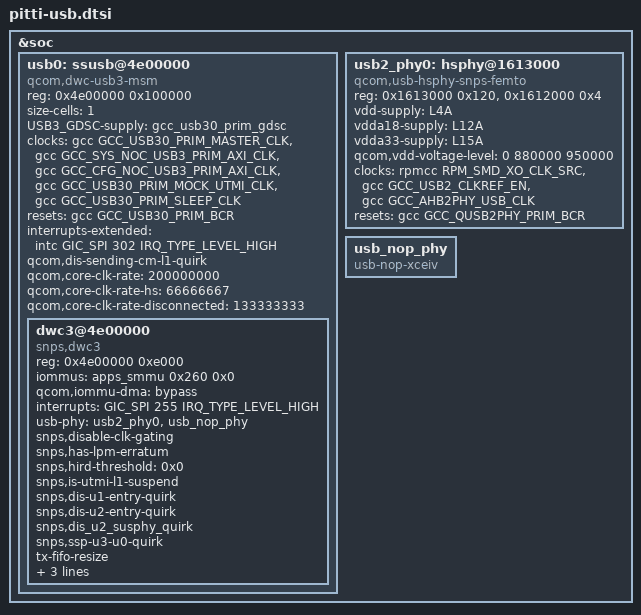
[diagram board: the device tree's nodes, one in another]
#include <dt-bindings/clock/qcom,gcc-pitti.h>

&soc {
	usb0: ssusb@4e00000 {
		compatible = "qcom,dwc-usb3-msm";
		reg = <0x4e00000 0x100000>;
		reg-names = "core_base";
		#address-cells = <1>; size-cells = <1>;
		ranges;

		USB3_GDSC-supply = <&gcc_usb30_prim_gdsc>;
		clocks = <&gcc GCC_USB30_PRIM_MASTER_CLK>,
			<&gcc GCC_SYS_NOC_USB3_PRIM_AXI_CLK>,
			<&gcc GCC_CFG_NOC_USB3_PRIM_AXI_CLK>,
			<&gcc GCC_USB30_PRIM_MOCK_UTMI_CLK>,
			<&gcc GCC_USB30_PRIM_SLEEP_CLK>;
		clock-names = "core_clk", "iface_clk", "bus_aggr_clk",
					"utmi_clk", "sleep_clk";

		resets = <&gcc GCC_USB30_PRIM_BCR>;
		reset-names = "core_reset";

		interrupts-extended = <&intc GIC_SPI 302 IRQ_TYPE_LEVEL_HIGH>;
		interrupt-names = "pwr_event_irq";

		qcom,dis-sending-cm-l1-quirk;

		qcom,core-clk-rate = <200000000>;
		qcom,core-clk-rate-hs = <66666667>;
		qcom,core-clk-rate-disconnected = <133333333>;

		dwc3@4e00000 {
			compatible = "snps,dwc3";
			reg = <0x4e00000 0xe000>;

			iommus = <&apps_smmu 0x260 0x0>;
			qcom,iommu-dma = "bypass";

			interrupts = <GIC_SPI 255 IRQ_TYPE_LEVEL_HIGH>;
			usb-phy = <&usb2_phy0>, <&usb_nop_phy>;
			snps,disable-clk-gating;
			snps,has-lpm-erratum;
			snps,hird-threshold = /bits/ 8 <0x0>;
			snps,is-utmi-l1-suspend;
			snps,dis-u1-entry-quirk;
			snps,dis-u2-entry-quirk;
			snps,dis_u2_susphy_quirk;
			snps,ssp-u3-u0-quirk;
			tx-fifo-resize;
			dr_mode = "peripheral";
			maximum-speed = "high-speed";
			usb-role-switch;
		};
	};

	/* USB port related High Speed PHY */
	usb2_phy0: hsphy@1613000 {
		compatible = "qcom,usb-hsphy-snps-femto";
		reg = <0x1613000 0x120>,
			<0x1612000 0x4>;
		reg-names = "hsusb_phy_base",
				"eud_enable_reg";

		vdd-supply = <&L4A>;
		vdda18-supply = <&L12A>;
		vdda33-supply = <&L15A>;
		qcom,vdd-voltage-level = <0 880000 950000>;

		clocks = <&rpmcc RPM_SMD_XO_CLK_SRC>,
			<&gcc GCC_USB2_CLKREF_EN>,
			<&gcc GCC_AHB2PHY_USB_CLK>;
		clock-names = "ref_clk_src", "ref_clk", "cfg_ahb_clk";

		resets = <&gcc GCC_QUSB2PHY_PRIM_BCR>;
		reset-names = "phy_reset";
	};

	usb_nop_phy: usb_nop_phy {
		compatible = "usb-nop-xceiv";
	};
};
